VERSION ""

NS_ :

BS_:

BU_: AN400ECU Third_Party_Device

BO_ 218099784 MSGID_0X0CFFF048: 8 AN400ECU
 SG_ RPM : 7|16@0+ (1.0,0) [0|0] "rpm"  Third_Party_Device

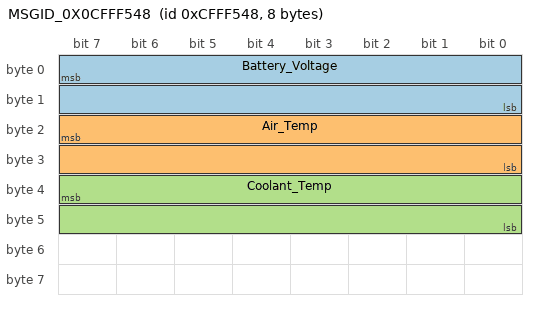
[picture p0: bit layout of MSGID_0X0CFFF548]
BO_ 218101064 MSGID_0X0CFFF548: 8 AN400ECU
 SG_ Battery_Voltage : 7|16@0- (0.01,0) [0|0] "Volts"  Third_Party_Device
 SG_ Air_Temp : 23|16@0- (0.1,0) [0|0] "C/F"  Third_Party_Device
 SG_ Coolant_Temp : 39|16@0- (0.1,0) [0|0] "C/F"  Third_Party_Device

BO_ 218101320 MSGID_0X0CFFF648: 8 AN400ECU
 SG_ Thermistor1_Temp : 7|16@0- (0.1,0) [0|0] "C/F"  Third_Party_Device
 SG_ Thermistor2_Temp : 23|16@0- (0.1,0) [0|0] "C/F"  Third_Party_Device
